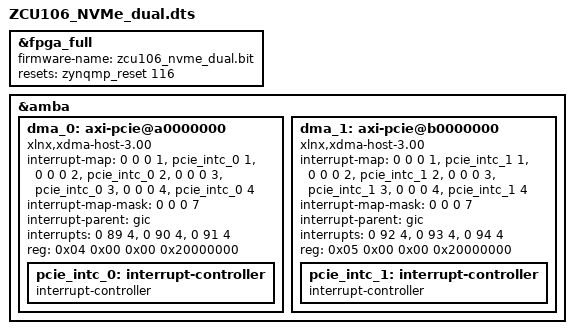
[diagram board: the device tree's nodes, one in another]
/dts-v1/;
/plugin/;
/ {

    fragment@0 {
        target = <&fpga_full>;
        overlay0: __overlay__ {
            #address-cells = <2>;
            #size-cells = <2>;
            firmware-name = "zcu106_nvme_dual.bit";
            resets = <&zynqmp_reset 116>;
        };
    };


    fragment@1 {
        target = <&amba>;
        overlay1: __overlay__ {
		dma_0: axi-pcie@a0000000 {
			#address-cells = <3>;
			#interrupt-cells = <1>;
			#size-cells = <2>;
			compatible = "xlnx,xdma-host-3.00";
			device_type = "pci";
			interrupt-map = <0 0 0 1 &pcie_intc_0 1>, <0 0 0 2 &pcie_intc_0 2>, <0 0 0 3 &pcie_intc_0 3>, <0 0 0 4 &pcie_intc_0 4>;
			interrupt-map-mask = <0 0 0 7>;
			interrupt-parent = <&gic>;
		        interrupt-names = "misc", "msi0", "msi1";
		        interrupts = <0 89 4>, <0 90 4>, <0 91 4>;
			/*ranges = <0x02000000 0x00000000 0xB0000000 0x0 0xB0000000 0x00000000 0x01000000>,
			    <0x43000000 0x00000005 0x00000000 0x00000005 0x00000000 0x00000000 0x01000000>; */
                        ranges = <0x2000000 0x00 0xa0000000 0x00 0xa0000000 0x00 0x10000000>;
                        reg = <0x04 0x00 0x00 0x20000000>;

			pcie_intc_0: interrupt-controller {
			    #address-cells = <0>;
			    #interrupt-cells = <1>;
			    interrupt-controller ;
			};
		    };

                dma_1: axi-pcie@b0000000 {
                        #address-cells = <3>;
                        #interrupt-cells = <1>;
                        #size-cells = <2>;
                        compatible = "xlnx,xdma-host-3.00";
                        device_type = "pci";
                        interrupt-map = <0 0 0 1 &pcie_intc_1 1>, <0 0 0 2 &pcie_intc_1 2>, <0 0 0 3 &pcie_intc_1 3>, <0 0 0 4 &pcie_intc_1 4>;
                        interrupt-map-mask = <0 0 0 7>;
                        interrupt-parent = <&gic>;
                        interrupt-names = "misc", "msi0", "msi1";
                        interrupts = <0 92 4>, <0 93 4>, <0 94 4>;
                        ranges = <0x2000000 0x00 0xb0000000 0x00 0xb0000000 0x00 0x10000000>;
                        reg = <0x05 0x00 0x00 0x20000000>;

                        pcie_intc_1: interrupt-controller {
                            #address-cells = <0>;
                            #interrupt-cells = <1>;
                            interrupt-controller ;
                        };
                    };


        };
    };

};

